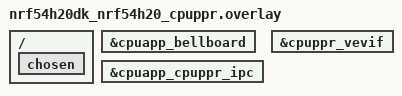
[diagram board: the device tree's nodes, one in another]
/*
 * Copyright (c) 2025 Nordic Semiconductor ASA
 *
 * SPDX-License-Identifier: Apache-2.0
 */

&cpuapp_bellboard {
	status = "okay";
};

ipc0: &cpuapp_cpuppr_ipc {
	status = "okay";
};

&cpuppr_vevif {
	status = "okay";
};

/ {
	chosen {
		/delete-property/ zephyr,bt-hci;
	};
};
